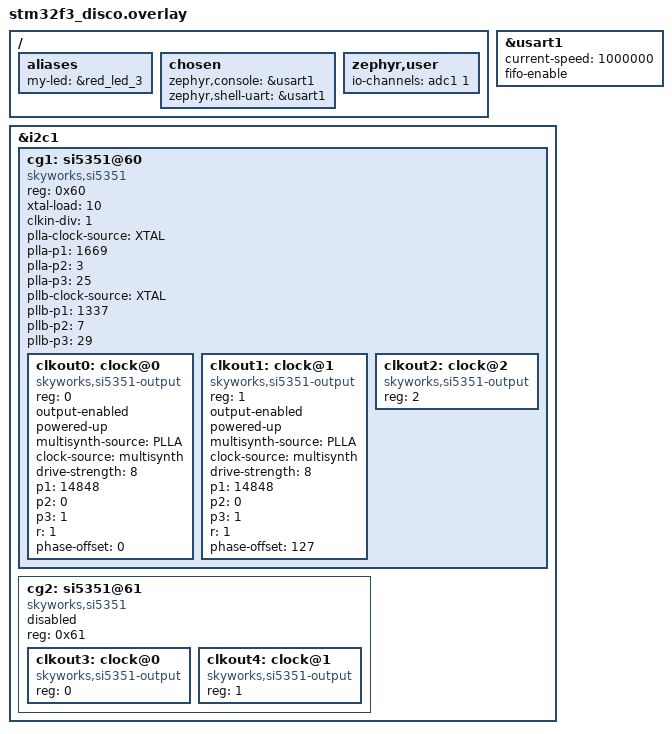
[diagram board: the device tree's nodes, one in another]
/ {
    aliases {
        my-led = &red_led_3;
    };
    chosen {
        zephyr,console = &usart1;
        zephyr,shell-uart = &usart1;
    };
    zephyr,user {
        /* adjust channel number according to pinmux in board.dts */
        io-channels = <&adc1 1>;
    };
};

&usart1 {
    current-speed = <1000000>;
    fifo-enable;
};

&i2c1 {
    cg1: si5351@60 {
        compatible = "skyworks,si5351";
        reg = <0x60>;
        #address-cells = <1>;
        #size-cells = <0>;

        xtal-load = <10>;
        clkin-div = <1>;

        plla-clock-source = "XTAL";
        plla-p1 = <1669>;
        plla-p2 = <3>;
        plla-p3 = <25>;

        pllb-clock-source = "XTAL";
        pllb-p1 = <1337>;
        pllb-p2 = <7>;
        pllb-p3 = <29>;

        clkout0: clock@0 {
            compatible = "skyworks,si5351-output";
            reg = <0>;
            #clock-cells = <0>;
            output-enabled;
            powered-up;
            multisynth-source = "PLLA";
            clock-source = "multisynth";
            drive-strength = <8>;
            p1 = <14848>;
            p2 = <0>;
            p3 = <1>;
            r = <1>;
            phase-offset = <0>;
        };

        clkout1: clock@1 {
            compatible = "skyworks,si5351-output";
            reg = <1>;
            #clock-cells = <0>;
            output-enabled;
            powered-up;
            multisynth-source = "PLLA";
            clock-source = "multisynth";
            drive-strength = <8>;
            p1 = <14848>;
            p2 = <0>;
            p3 = <1>;
            r = <1>;
            phase-offset = <127>;
        };

        clkout2: clock@2 {
            compatible = "skyworks,si5351-output";
            reg = <2>;
            #clock-cells = <0>;
        };
    };
    cg2: si5351@61 {
        compatible = "skyworks,si5351";
        reg = <0x61>;
        #address-cells = <1>;
        #size-cells = <0>;
        status = "disabled";

        clkout3: clock@0 {
            compatible = "skyworks,si5351-output";
            reg = <0>;
            #clock-cells = <0>;
        };

        clkout4: clock@1 {
            compatible = "skyworks,si5351-output";
            reg = <1>;
            #clock-cells = <0>;
        };
    };
};

/* ADC at PE7 */
/* Not really working yet
&adc3 {
    pinctrl-0 = <&adc3_in13_pe7>;
    pinctrl-names = "default";
    st,adc-clock-source = "SYNC";
    st,adc-prescaler = <2>;
    status = "okay";
};
 */
/*
&adc1 {
    pinctrl-0 = <&adc1_in1_pa0>;
    pinctrl-names = "default";
    st,adc-clock-source = "SYNC";
    st,adc-prescaler = <2>;
    status = "okay";

    channel@0 {
        reg = <0>;
        zephyr,gain = "ADC_GAIN_1";
        zephyr,reference = "ADC_REF_INTERNAL";
        zephyr,acquisition-time = <ADC_ACQ_TIME_DEFAULT>;
        zephyr,resolution = <12>;
    };

};*/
